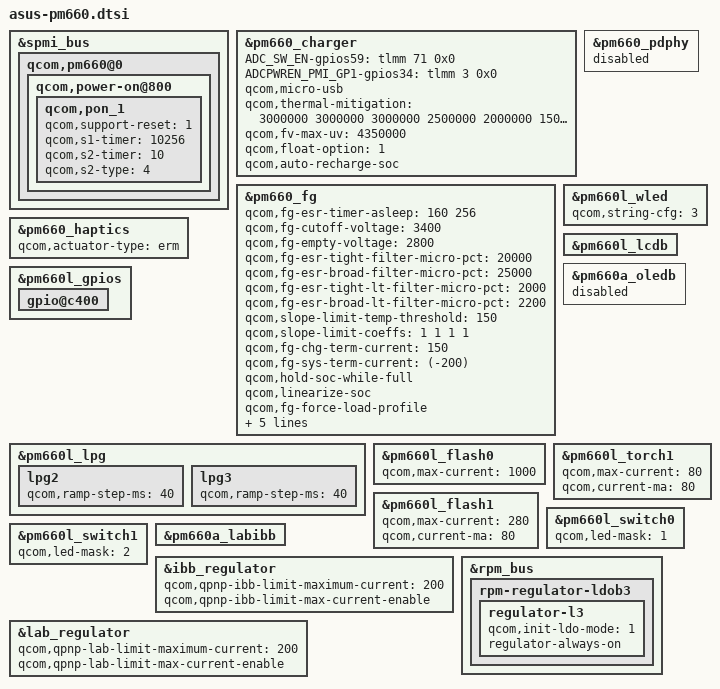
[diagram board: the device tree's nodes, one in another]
// SPDX-License-Identifier: GPL-2.0
// Copyright (C) 2021 Atom-X-Devs < https://www.github.com/Atom-X-Devs >

// asus pm660.dtsi specific diff
&spmi_bus {
	qcom,pm660@0 {
		qcom,power-on@800 {
			qcom,pon_1 {
				qcom,support-reset = <1>;
				qcom,s1-timer = <10256>;
				qcom,s2-timer = <10>;
				qcom,s2-type = <4>;
			};
		};
	};
};

&pm660_charger {
	ADC_SW_EN-gpios59 = <&tlmm 71 0x0>;
	ADCPWREN_PMI_GP1-gpios34 = <&tlmm 3 0x0>;
	qcom,micro-usb;
	qcom,thermal-mitigation = <3000000 3000000 3000000 2500000 2000000 1500000>;
	qcom,fv-max-uv = <4350000>;
	qcom,float-option = <1>;
	qcom,auto-recharge-soc;
};

&pm660_pdphy {
	status = "disabled";
};

&pm660_fg {
	qcom,fg-esr-timer-asleep = <160 256>;
	qcom,fg-cutoff-voltage = <3400>;
	qcom,fg-empty-voltage = <2800>;
	qcom,fg-esr-tight-filter-micro-pct = <20000>;
	qcom,fg-esr-broad-filter-micro-pct = <25000>;
	qcom,fg-esr-tight-lt-filter-micro-pct = <2000>;
	qcom,fg-esr-broad-lt-filter-micro-pct = <2200>;
	qcom,slope-limit-temp-threshold = <150>;
	qcom,slope-limit-coeffs = <1 1 1 1>;
	qcom,fg-chg-term-current = <150>;
	qcom,fg-sys-term-current = <(-200)>;
	qcom,hold-soc-while-full;
	qcom,linearize-soc;
	qcom,fg-force-load-profile;
	qcom,fg-jeita-hyst-temp = <3>;
	qcom,fg-recharge-voltage = <4150>;
	qcom,fg-recharge-soc-thr = <98>;
	qcom,fg-auto-recharge-soc;
	qcom,fg-rsense-sel=<1>;
};

&pm660_haptics {
	qcom,actuator-type = "erm";
};

// asus pm660a.dtsi diff
&pm660l_wled {
	status = "okay";
};

&pm660l_lcdb {
	status = "okay";
};

&pm660a_oledb {
	status = "disabled";
};

// asus pm660l.dtsi diff
&pm660l_gpios {
	gpio@c400 {
		status = "ok";
	};
};

&pm660l_wled {
	qcom,string-cfg = <3>;
};

&pm660l_lpg {
    // Green
    lpg2 {
        qcom,ramp-step-ms = <40>;
    };

    // Red
    lpg3 {
        qcom,ramp-step-ms = <40>;
    };
};

&pm660l_flash0 {
	qcom,max-current = <1000>;
};

&pm660l_flash1 {
	qcom,max-current = <280>;
	qcom,current-ma = <80>;
};

&pm660l_torch1 {
	qcom,max-current = <80>;
	qcom,current-ma = <80>;
};

&pm660l_switch0 {
	qcom,led-mask = <1>;
};

&pm660l_switch1 {
	qcom,led-mask = <2>;
};

&pm660a_labibb {
	status = "okay";
};

&ibb_regulator {
	qcom,qpnp-ibb-limit-maximum-current = <200>;
	qcom,qpnp-ibb-limit-max-current-enable;
};

&lab_regulator {
	qcom,qpnp-lab-limit-maximum-current = <200>;
	qcom,qpnp-lab-limit-max-current-enable;
};

&rpm_bus {
	rpm-regulator-ldob3 {
		regulator-l3 {
			qcom,init-ldo-mode = <1>;
			regulator-always-on;
		};
	};
};
